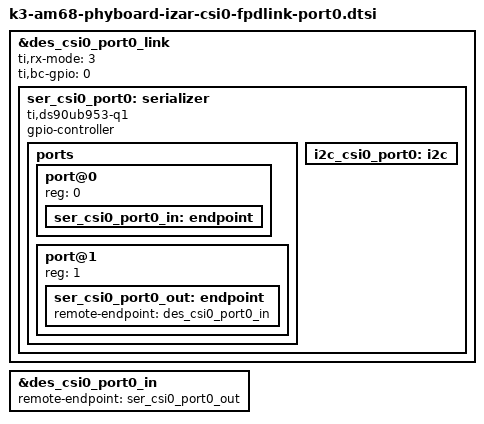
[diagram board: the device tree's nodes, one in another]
// SPDX-License-Identifier: (GPL-2.0+ OR MIT)
/*
 * Copyright (C) 2025 PHYTEC Messtechnik GmbH
 * Author: Steffen Hemer <s.hemer@phytec.de>
 */

#include "k3-am68-phyboard-izar-csi0-fpdlink.dtsi"

&des_csi0_port0_link {
	ti,rx-mode = <3>;
	ti,bc-gpio = <0>;

	ser_csi0_port0: serializer {
		compatible = "ti,ds90ub953-q1";

		gpio-controller;
		#gpio-cells = <2>;

		#clock-cells = <0>;

		ports {
			#address-cells = <0x1>;
			#size-cells = <0x0>;
			port@0 {
				reg = <0>;
				ser_csi0_port0_in: endpoint {};
			};

			port@1 {
				reg = <1>;
				ser_csi0_port0_out: endpoint {
					remote-endpoint = <&des_csi0_port0_in>;
				};
			};
		};

		i2c_csi0_port0: i2c {
			#address-cells = <1>;
			#size-cells = <0>;
		};
	};
};

&des_csi0_port0_in {
	remote-endpoint = <&ser_csi0_port0_out>;
};
